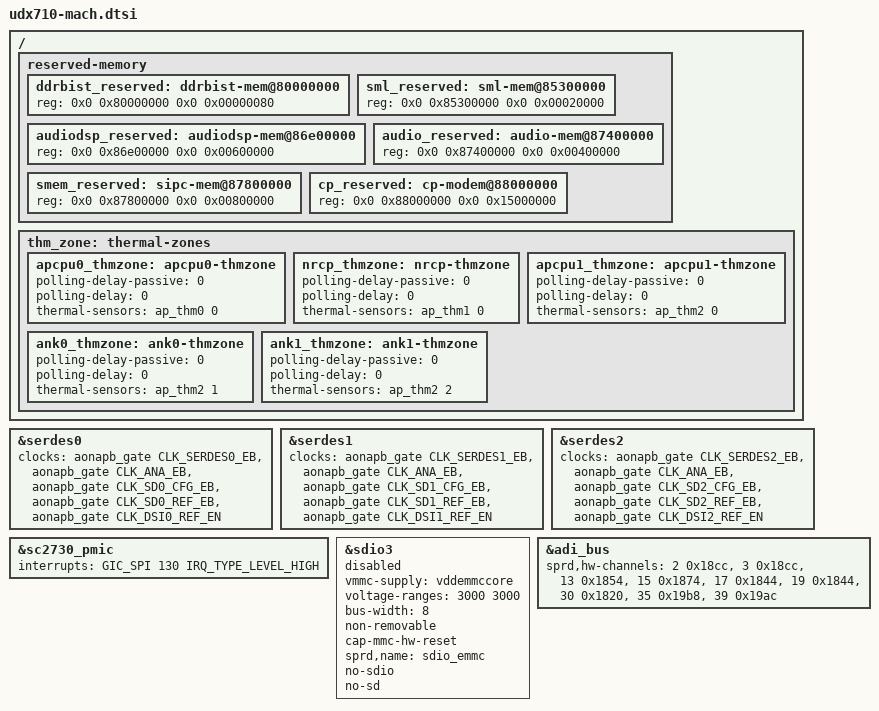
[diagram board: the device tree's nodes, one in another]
/*
 * Spreadtrum UDX710 board common DTS file
 *
 * Copyright (C) 2017, Spreadtrum Communications Inc.
 *
 * This file is licensed under a dual GPLv2 or X11 license.
 */

#include "udx710-modem.dtsi"

/ {
	reserved-memory {
		#address-cells = <2>;
		#size-cells = <2>;
		ranges;

		ddrbist_reserved: ddrbist-mem@80000000 {
			reg = <0x0 0x80000000 0x0 0x00000080>;
		};

		sml_reserved: sml-mem@85300000 {
			reg = <0x0 0x85300000 0x0 0x00020000>;
		};

		audiodsp_reserved: audiodsp-mem@86e00000 {
			reg = <0x0 0x86e00000 0x0 0x00600000>;
		};

		audio_reserved: audio-mem@87400000 {
			reg = <0x0 0x87400000 0x0 0x00400000>;
		};

		smem_reserved: sipc-mem@87800000 {
			reg = <0x0 0x87800000 0x0 0x00800000>;
		};

		cp_reserved: cp-modem@88000000 {
			reg = <0x0 0x88000000 0x0 0x15000000>;
		};
	};

	thm_zone: thermal-zones {

		apcpu0_thmzone: apcpu0-thmzone {
			polling-delay-passive = <0>;
			polling-delay = <0>;
			thermal-sensors = <&ap_thm0 0>;
		};

		nrcp_thmzone: nrcp-thmzone {
			polling-delay-passive = <0>;
			polling-delay = <0>;
			thermal-sensors = <&ap_thm1 0>;
		};

		apcpu1_thmzone: apcpu1-thmzone {
			polling-delay-passive = <0>;
			polling-delay = <0>;
			thermal-sensors = <&ap_thm2 0>;
		};

		ank0_thmzone: ank0-thmzone {
			polling-delay-passive = <0>;
			polling-delay = <0>;
			thermal-sensors = <&ap_thm2 1>;
		};

		ank1_thmzone: ank1-thmzone {
			polling-delay-passive = <0>;
			polling-delay = <0>;
			thermal-sensors = <&ap_thm2 2>;
		};
	};
};

&serdes0 {
	status = "okay";
	clock-names =
		"serdes_eb",
		"ana_eb",
		"dphy_cfg_eb",
		"dphy_ref_eb",
		"dsi_ref_eb";
	clocks =
		<&aonapb_gate CLK_SERDES0_EB>,
		<&aonapb_gate CLK_ANA_EB>,
		<&aonapb_gate CLK_SD0_CFG_EB>,
		<&aonapb_gate CLK_SD0_REF_EB>,
		<&aonapb_gate CLK_DSI0_REF_EN>;
};

&serdes1 {
	status = "okay";
	clock-names =
		"serdes_eb",
		"ana_eb",
		"dphy_cfg_eb",
		"dphy_ref_eb",
		"dsi_ref_eb";
	clocks =
		<&aonapb_gate CLK_SERDES1_EB>,
		<&aonapb_gate CLK_ANA_EB>,
		<&aonapb_gate CLK_SD1_CFG_EB>,
		<&aonapb_gate CLK_SD1_REF_EB>,
		<&aonapb_gate CLK_DSI1_REF_EN>;
};

&serdes2 {
	status = "okay";
	clock-names =
		"serdes_eb",
		"ana_eb",
		"dphy_cfg_eb",
		"dphy_ref_eb",
		"dsi_ref_eb";
	clocks =
		<&aonapb_gate CLK_SERDES2_EB>,
		<&aonapb_gate CLK_ANA_EB>,
		<&aonapb_gate CLK_SD2_CFG_EB>,
		<&aonapb_gate CLK_SD2_REF_EB>,
		<&aonapb_gate CLK_DSI2_REF_EN>;
};

&sc2730_pmic {
	interrupts = <GIC_SPI 130 IRQ_TYPE_LEVEL_HIGH>;
};

&sdio3 {
	vmmc-supply = <&vddemmccore>;
	voltage-ranges = <3000 3000>;
	bus-width = <8>;
	non-removable;
	cap-mmc-hw-reset;
	sprd,name = "sdio_emmc";
	no-sdio;
	no-sd;
	status = "disabled";
};

&adi_bus {
	sprd,hw-channels = <2 0x18cc>, <3 0x18cc>, <13 0x1854>, <15 0x1874>,
			<17 0x1844>, <19 0x1844>, <30 0x1820>, <35 0x19b8>, <39 0x19ac>;
};
